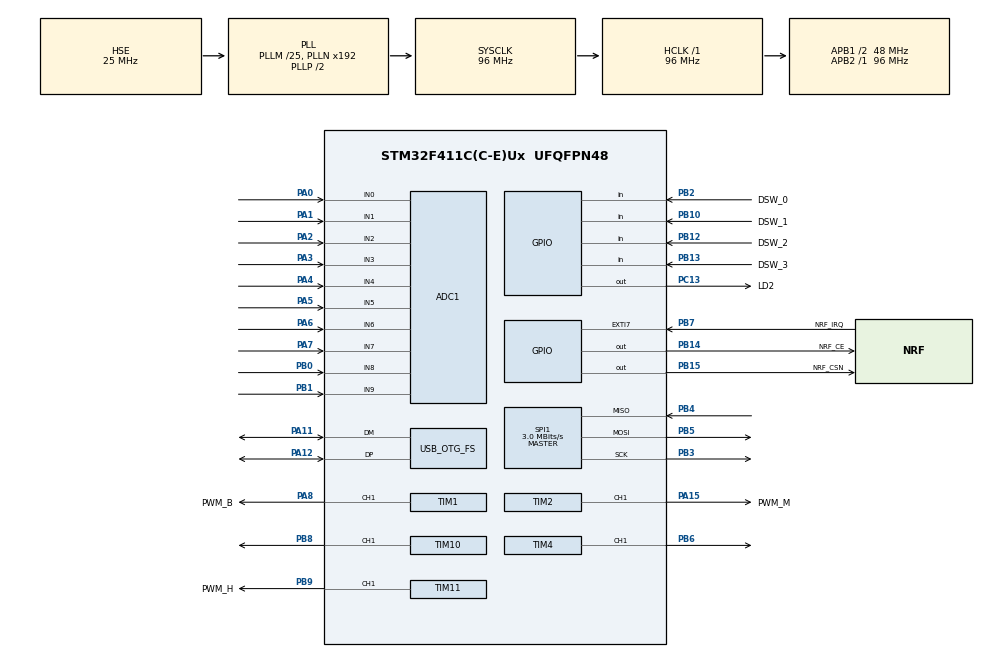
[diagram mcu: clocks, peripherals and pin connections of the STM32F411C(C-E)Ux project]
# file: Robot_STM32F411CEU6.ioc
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ADC1.Channel-0\#ChannelRegularConversion=ADC_CHANNEL_0
ADC1.NbrOfConversionFlag=1
ADC1.Rank-0\#ChannelRegularConversion=1
ADC1.SamplingTime-0\#ChannelRegularConversion=ADC_SAMPLETIME_3CYCLES
ADC1.master=1
Mcu.Family=STM32F4
Mcu.Name=STM32F411C(C-E)Ux
Mcu.Package=UFQFPN48
NVIC.OTG_FS_IRQn=true\:0\:0\:false\:false\:true\:false\:true\:true
NVIC.PriorityGroup=NVIC_PRIORITYGROUP_4
PA0-WKUP.Signal=ADCx_IN0
PA1.Signal=ADCx_IN1
PA11.Mode=Device_Only
PA11.Signal=USB_OTG_FS_DM
PA12.Mode=Device_Only
PA12.Signal=USB_OTG_FS_DP
PA13.Mode=Serial_Wire
PA13.Signal=SYS_JTMS-SWDIO
PA14.Mode=Serial_Wire
PA14.Signal=SYS_JTCK-SWCLK
PA15.GPIO_Label=PWM_M
PA15.GPIO_ModeDefaultPP=GPIO_MODE_AF_OD
PA15.Signal=S_TIM2_CH1_ETR
PA2.Signal=ADCx_IN2
PA3.Signal=ADCx_IN3
PA4.Signal=ADCx_IN4
PA5.Signal=ADCx_IN5
PA6.Signal=ADCx_IN6
PA7.Signal=ADCx_IN7
PA8.GPIO_Label=PWM_B
PA8.GPIO_ModeDefaultPP=GPIO_MODE_AF_OD
PA8.Signal=S_TIM1_CH1
PB0.Signal=ADCx_IN8
PB1.Signal=ADCx_IN9
PB10.GPIO_Label=DSW_1
PB10.GPIO_PuPd=GPIO_PULLUP
PB10.Signal=GPIO_Input
PB12.GPIO_Label=DSW_2
PB12.GPIO_PuPd=GPIO_PULLUP
PB12.Signal=GPIO_Input
PB13.GPIO_Label=DSW_3
PB13.GPIO_PuPd=GPIO_PULLUP
PB13.Signal=GPIO_Input
PB14.GPIO_Label=NRF_CE
PB14.Signal=GPIO_Output
PB15.GPIO_Label=NRF_CSN
PB15.Signal=GPIO_Output
PB2.GPIO_Label=DSW_0
PB2.GPIO_PuPd=GPIO_PULLUP
PB2.Signal=GPIO_Input
PB3.Mode=Full_Duplex_Master
PB3.Signal=SPI1_SCK
PB4.Mode=Full_Duplex_Master
PB4.Signal=SPI1_MISO
PB5.Mode=Full_Duplex_Master
PB5.Signal=SPI1_MOSI
PB6.Signal=S_TIM4_CH1
PB7.GPIO_Label=NRF_IRQ
PB7.Signal=GPXTI7
PB8.Signal=S_TIM10_CH1
PB9.GPIO_Label=PWM_H
PB9.GPIO_ModeDefaultPP=GPIO_MODE_AF_OD
PB9.Signal=S_TIM11_CH1
PC13-ANTI_TAMP.GPIO_Label=LD2
PC13-ANTI_TAMP.Signal=GPIO_Output
PC14-OSC32_IN.Mode=LSE-External-Oscillator
PC14-OSC32_IN.Signal=RCC_OSC32_IN
PC15-OSC32_OUT.Mode=LSE-External-Oscillator
PC15-OSC32_OUT.Signal=RCC_OSC32_OUT
PH0\ -\ OSC_IN.Mode=HSE-External-Oscillator
PH0\ -\ OSC_IN.Signal=RCC_OSC_IN
PH1\ -\ OSC_OUT.Mode=HSE-External-Oscillator
PH1\ -\ OSC_OUT.Signal=RCC_OSC_OUT
ProjectManager.HeapSize=0x200
ProjectManager.StackSize=0x400
ProjectManager.TargetToolchain=STM32CubeIDE
RCC.48MHZClocksFreq_Value=48000000
RCC.AHBFreq_Value=96000000
RCC.APB1CLKDivider=RCC_HCLK_DIV2
RCC.APB1Freq_Value=48000000
RCC.APB1TimCLKDivider=2
RCC.APB1TimFreq_Value=96000000
RCC.APB2Freq_Value=96000000
RCC.APB2TimFreq_Value=96000000
RCC.CortexFreq_Value=96000000
RCC.HCLKFreq_Value=96000000
RCC.HSE_VALUE=25000000
RCC.HSI_VALUE=16000000
RCC.PLLM=25
RCC.SYSCLKFreq_VALUE=96000000
RCC.SYSCLKSource=RCC_SYSCLKSOURCE_PLLCLK
RCC.VCOOutputFreq_Value=192000000
SH.ADCx_IN0.0=ADC1_IN0,IN0
SH.ADCx_IN1.0=ADC1_IN1,IN1
SH.ADCx_IN2.0=ADC1_IN2,IN2
SH.ADCx_IN3.0=ADC1_IN3,IN3
SH.ADCx_IN4.0=ADC1_IN4,IN4
SH.ADCx_IN5.0=ADC1_IN5,IN5
SH.ADCx_IN6.0=ADC1_IN6,IN6
SH.ADCx_IN7.0=ADC1_IN7,IN7
SH.ADCx_IN8.0=ADC1_IN8,IN8
SH.ADCx_IN9.0=ADC1_IN9,IN9
SH.S_TIM10_CH1.0=TIM10_CH1,PWM Generation1 CH1
SH.S_TIM11_CH1.0=TIM11_CH1,PWM Generation1 CH1
SH.S_TIM1_CH1.0=TIM1_CH1,PWM Generation1 CH1
SH.S_TIM2_CH1_ETR.0=TIM2_CH1,PWM Generation1 CH1
SH.S_TIM4_CH1.0=TIM4_CH1,PWM Generation1 CH1
SPI1.BaudRatePrescaler=SPI_BAUDRATEPRESCALER_32
SPI1.CalculateBaudRate=3.0 MBits/s
SPI1.Direction=SPI_DIRECTION_2LINES
SPI1.Mode=SPI_MODE_MASTER
SPI1.VirtualType=VM_MASTER
TIM1.Channel-PWM\ Generation1\ CH1=TIM_CHANNEL_1
TIM1.Period=19999
TIM1.Prescaler=95
TIM10.Channel=TIM_CHANNEL_1
TIM10.Period=65535
TIM10.Prescaler=0
TIM11.Channel=TIM_CHANNEL_1
TIM11.Period=20000
TIM11.Prescaler=95
TIM2.Channel-PWM\ Generation1\ CH1=TIM_CHANNEL_1
TIM2.Period=20000
TIM2.Prescaler=95
TIM4.Channel-PWM\ Generation1\ CH1=TIM_CHANNEL_1
USB_DEVICE.CLASS_NAME_FS=CDC
USB_DEVICE.VirtualMode=Cdc
USB_DEVICE.VirtualModeFS=Cdc_FS
USB_OTG_FS.VirtualMode=Device_Only
VP_TIM10_VS_ClockSourceINT.Mode=Enable_Timer
VP_TIM11_VS_ClockSourceINT.Mode=Enable_Timer
VP_USB_DEVICE_VS_USB_DEVICE_CDC_FS.Mode=CDC_FS
board=custom

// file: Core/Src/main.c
/* USER CODE BEGIN Header */
/**
  ******************************************************************************
  * @file           : main.c
  * @brief          : Main program body
  ******************************************************************************
  * @attention
  *
  * Copyright (c) 2025 STMicroelectronics.
  * All rights reserved.
  *
  * This software is licensed under terms that can be found in the LICENSE file
  * in the root directory of this software component.
  * If no LICENSE file comes with this software, it is provided AS-IS.
  *
  ******************************************************************************
  */
/* USER CODE END Header */
#include "main.h"
#include "usb_device.h"

/* USER CODE BEGIN Includes */
#include "movement.h"
/* USER CODE END Includes */

ADC_HandleTypeDef hadc1;

SPI_HandleTypeDef hspi1;

TIM_HandleTypeDef htim1;
TIM_HandleTypeDef htim2;
TIM_HandleTypeDef htim4;
TIM_HandleTypeDef htim10;
TIM_HandleTypeDef htim11;

void SystemClock_Config(void);
static void MX_GPIO_Init(void);
static void MX_ADC1_Init(void);
static void MX_SPI1_Init(void);
static void MX_TIM1_Init(void);
static void MX_TIM2_Init(void);
static void MX_TIM4_Init(void);
static void MX_TIM10_Init(void);
static void MX_TIM11_Init(void);

int main(void)
{

  /* MCU Configuration--------------------------------------------------------*/

  /* Reset of all peripherals, Initializes the Flash interface and the Systick. */
  HAL_Init();

  /* Configure the system clock */
  SystemClock_Config();

  /* Initialize all configured peripherals */
  MX_GPIO_Init();
  MX_ADC1_Init();
  MX_SPI1_Init();
  MX_USB_DEVICE_Init();
  MX_TIM1_Init();
  MX_TIM2_Init();
  MX_TIM4_Init();
  MX_TIM10_Init();
  MX_TIM11_Init();
  /* USER CODE BEGIN 2 */
  movement();
  /* USER CODE END 2 */

  /* Infinite loop */
  while (1)
  {

  }
}

void SystemClock_Config(void)
{
  RCC_OscInitTypeDef RCC_OscInitStruct = {0};
  RCC_ClkInitTypeDef RCC_ClkInitStruct = {0};

  /** Configure the main internal regulator output voltage
  */
  __HAL_RCC_PWR_CLK_ENABLE();
  __HAL_PWR_VOLTAGESCALING_CONFIG(PWR_REGULATOR_VOLTAGE_SCALE1);

  /** Initializes the RCC Oscillators according to the specified parameters
  * in the RCC_OscInitTypeDef structure.
  */
  RCC_OscInitStruct.OscillatorType = RCC_OSCILLATORTYPE_HSE;
  RCC_OscInitStruct.HSEState = RCC_HSE_ON;
  RCC_OscInitStruct.PLL.PLLState = RCC_PLL_ON;
  RCC_OscInitStruct.PLL.PLLSource = RCC_PLLSOURCE_HSE;
  RCC_OscInitStruct.PLL.PLLM = 25;
  RCC_OscInitStruct.PLL.PLLN = 192;
  RCC_OscInitStruct.PLL.PLLP = RCC_PLLP_DIV2;
  RCC_OscInitStruct.PLL.PLLQ = 4;
  if (HAL_RCC_OscConfig(&RCC_OscInitStruct) != HAL_OK)
  {
    Error_Handler();
  }

  /** Initializes the CPU, AHB and APB buses clocks
  */
  RCC_ClkInitStruct.ClockType = RCC_CLOCKTYPE_HCLK|RCC_CLOCKTYPE_SYSCLK
                              |RCC_CLOCKTYPE_PCLK1|RCC_CLOCKTYPE_PCLK2;
  RCC_ClkInitStruct.SYSCLKSource = RCC_SYSCLKSOURCE_PLLCLK;
  RCC_ClkInitStruct.AHBCLKDivider = RCC_SYSCLK_DIV1;
  RCC_ClkInitStruct.APB1CLKDivider = RCC_HCLK_DIV2;
  RCC_ClkInitStruct.APB2CLKDivider = RCC_HCLK_DIV1;

  if (HAL_RCC_ClockConfig(&RCC_ClkInitStruct, FLASH_LATENCY_3) != HAL_OK)
  {
    Error_Handler();
  }
}

static void MX_ADC1_Init(void)
{

  ADC_ChannelConfTypeDef sConfig = {0};

  /** Configure the global features of the ADC (Clock, Resolution, Data Alignment and number of conversion)
  */
  hadc1.Instance = ADC1;
  hadc1.Init.ClockPrescaler = ADC_CLOCK_SYNC_PCLK_DIV4;
  hadc1.Init.Resolution = ADC_RESOLUTION_12B;
  hadc1.Init.ScanConvMode = DISABLE;
  hadc1.Init.ContinuousConvMode = DISABLE;
  hadc1.Init.DiscontinuousConvMode = DISABLE;
  hadc1.Init.ExternalTrigConvEdge = ADC_EXTERNALTRIGCONVEDGE_NONE;
  hadc1.Init.ExternalTrigConv = ADC_SOFTWARE_START;
  hadc1.Init.DataAlign = ADC_DATAALIGN_RIGHT;
  hadc1.Init.NbrOfConversion = 1;
  hadc1.Init.DMAContinuousRequests = DISABLE;
  hadc1.Init.EOCSelection = ADC_EOC_SINGLE_CONV;
  if (HAL_ADC_Init(&hadc1) != HAL_OK)
  {
    Error_Handler();
  }

  /** Configure for the selected ADC regular channel its corresponding rank in the sequencer and its sample time.
  */
  sConfig.Channel = ADC_CHANNEL_0;
  sConfig.Rank = 1;
  sConfig.SamplingTime = ADC_SAMPLETIME_3CYCLES;
  if (HAL_ADC_ConfigChannel(&hadc1, &sConfig) != HAL_OK)
  {
    Error_Handler();
  }

}

static void MX_SPI1_Init(void)
{

  /* SPI1 parameter configuration*/
  hspi1.Instance = SPI1;
  hspi1.Init.Mode = SPI_MODE_MASTER;
  hspi1.Init.Direction = SPI_DIRECTION_2LINES;
  hspi1.Init.DataSize = SPI_DATASIZE_8BIT;
  hspi1.Init.CLKPolarity = SPI_POLARITY_LOW;
  hspi1.Init.CLKPhase = SPI_PHASE_1EDGE;
  hspi1.Init.NSS = SPI_NSS_SOFT;
  hspi1.Init.BaudRatePrescaler = SPI_BAUDRATEPRESCALER_32;
  hspi1.Init.FirstBit = SPI_FIRSTBIT_MSB;
  hspi1.Init.TIMode = SPI_TIMODE_DISABLE;
  hspi1.Init.CRCCalculation = SPI_CRCCALCULATION_DISABLE;
  hspi1.Init.CRCPolynomial = 10;
  if (HAL_SPI_Init(&hspi1) != HAL_OK)
  {
    Error_Handler();
  }

}

static void MX_TIM1_Init(void)
{

  TIM_MasterConfigTypeDef sMasterConfig = {0};
  TIM_OC_InitTypeDef sConfigOC = {0};
  TIM_BreakDeadTimeConfigTypeDef sBreakDeadTimeConfig = {0};

  htim1.Instance = TIM1;
  htim1.Init.Prescaler = 95;
  htim1.Init.CounterMode = TIM_COUNTERMODE_UP;
  htim1.Init.Period = 19999;
  htim1.Init.ClockDivision = TIM_CLOCKDIVISION_DIV1;
  htim1.Init.RepetitionCounter = 0;
  htim1.Init.AutoReloadPreload = TIM_AUTORELOAD_PRELOAD_DISABLE;
  if (HAL_TIM_PWM_Init(&htim1) != HAL_OK)
  {
    Error_Handler();
  }
  sMasterConfig.MasterOutputTrigger = TIM_TRGO_RESET;
  sMasterConfig.MasterSlaveMode = TIM_MASTERSLAVEMODE_DISABLE;
  if (HAL_TIMEx_MasterConfigSynchronization(&htim1, &sMasterConfig) != HAL_OK)
  {
    Error_Handler();
  }
  sConfigOC.OCMode = TIM_OCMODE_PWM1;
  sConfigOC.Pulse = 0;
  sConfigOC.OCPolarity = TIM_OCPOLARITY_HIGH;
  sConfigOC.OCNPolarity = TIM_OCNPOLARITY_HIGH;
  sConfigOC.OCFastMode = TIM_OCFAST_DISABLE;
  sConfigOC.OCIdleState = TIM_OCIDLESTATE_RESET;
  sConfigOC.OCNIdleState = TIM_OCNIDLESTATE_RESET;
  if (HAL_TIM_PWM_ConfigChannel(&htim1, &sConfigOC, TIM_CHANNEL_1) != HAL_OK)
  {
    Error_Handler();
  }
  sBreakDeadTimeConfig.OffStateRunMode = TIM_OSSR_DISABLE;
  sBreakDeadTimeConfig.OffStateIDLEMode = TIM_OSSI_DISABLE;
  sBreakDeadTimeConfig.LockLevel = TIM_LOCKLEVEL_OFF;
  sBreakDeadTimeConfig.DeadTime = 0;
  sBreakDeadTimeConfig.BreakState = TIM_BREAK_DISABLE;
  sBreakDeadTimeConfig.BreakPolarity = TIM_BREAKPOLARITY_HIGH;
  sBreakDeadTimeConfig.AutomaticOutput = TIM_AUTOMATICOUTPUT_DISABLE;
  if (HAL_TIMEx_ConfigBreakDeadTime(&htim1, &sBreakDeadTimeConfig) != HAL_OK)
  {
    Error_Handler();
  }
  HAL_TIM_MspPostInit(&htim1);

}

static void MX_TIM2_Init(void)
{

  TIM_MasterConfigTypeDef sMasterConfig = {0};
  TIM_OC_InitTypeDef sConfigOC = {0};

  htim2.Instance = TIM2;
  htim2.Init.Prescaler = 95;
  htim2.Init.CounterMode = TIM_COUNTERMODE_UP;
  htim2.Init.Period = 20000;
  htim2.Init.ClockDivision = TIM_CLOCKDIVISION_DIV1;
  htim2.Init.AutoReloadPreload = TIM_AUTORELOAD_PRELOAD_DISABLE;
  if (HAL_TIM_PWM_Init(&htim2) != HAL_OK)
  {
    Error_Handler();
  }
  sMasterConfig.MasterOutputTrigger = TIM_TRGO_RESET;
  sMasterConfig.MasterSlaveMode = TIM_MASTERSLAVEMODE_DISABLE;
  if (HAL_TIMEx_MasterConfigSynchronization(&htim2, &sMasterConfig) != HAL_OK)
  {
    Error_Handler();
  }
  sConfigOC.OCMode = TIM_OCMODE_PWM1;
  sConfigOC.Pulse = 0;
  sConfigOC.OCPolarity = TIM_OCPOLARITY_HIGH;
  sConfigOC.OCFastMode = TIM_OCFAST_DISABLE;
  if (HAL_TIM_PWM_ConfigChannel(&htim2, &sConfigOC, TIM_CHANNEL_1) != HAL_OK)
  {
    Error_Handler();
  }
  HAL_TIM_MspPostInit(&htim2);

}

static void MX_TIM4_Init(void)
{

  TIM_MasterConfigTypeDef sMasterConfig = {0};
  TIM_OC_InitTypeDef sConfigOC = {0};

  htim4.Instance = TIM4;
  htim4.Init.Prescaler = 0;
  htim4.Init.CounterMode = TIM_COUNTERMODE_UP;
  htim4.Init.Period = 65535;
  htim4.Init.ClockDivision = TIM_CLOCKDIVISION_DIV1;
  htim4.Init.AutoReloadPreload = TIM_AUTORELOAD_PRELOAD_DISABLE;
  if (HAL_TIM_PWM_Init(&htim4) != HAL_OK)
  {
    Error_Handler();
  }
  sMasterConfig.MasterOutputTrigger = TIM_TRGO_RESET;
  sMasterConfig.MasterSlaveMode = TIM_MASTERSLAVEMODE_DISABLE;
  if (HAL_TIMEx_MasterConfigSynchronization(&htim4, &sMasterConfig) != HAL_OK)
  {
    Error_Handler();
  }
  sConfigOC.OCMode = TIM_OCMODE_PWM1;
  sConfigOC.Pulse = 0;
  sConfigOC.OCPolarity = TIM_OCPOLARITY_HIGH;
  sConfigOC.OCFastMode = TIM_OCFAST_DISABLE;
  if (HAL_TIM_PWM_ConfigChannel(&htim4, &sConfigOC, TIM_CHANNEL_1) != HAL_OK)
  {
    Error_Handler();
  }
  HAL_TIM_MspPostInit(&htim4);

}

static void MX_TIM10_Init(void)
{

  TIM_OC_InitTypeDef sConfigOC = {0};

  htim10.Instance = TIM10;
  htim10.Init.Prescaler = 0;
  htim10.Init.CounterMode = TIM_COUNTERMODE_UP;
  htim10.Init.Period = 65535;
  htim10.Init.ClockDivision = TIM_CLOCKDIVISION_DIV1;
  htim10.Init.AutoReloadPreload = TIM_AUTORELOAD_PRELOAD_DISABLE;
  if (HAL_TIM_Base_Init(&htim10) != HAL_OK)
  {
    Error_Handler();
  }
  if (HAL_TIM_PWM_Init(&htim10) != HAL_OK)
  {
    Error_Handler();
  }
  sConfigOC.OCMode = TIM_OCMODE_PWM1;
  sConfigOC.Pulse = 0;
  sConfigOC.OCPolarity = TIM_OCPOLARITY_HIGH;
  sConfigOC.OCFastMode = TIM_OCFAST_DISABLE;
  if (HAL_TIM_PWM_ConfigChannel(&htim10, &sConfigOC, TIM_CHANNEL_1) != HAL_OK)
  {
    Error_Handler();
  }
  HAL_TIM_MspPostInit(&htim10);

}

static void MX_TIM11_Init(void)
{

  TIM_OC_InitTypeDef sConfigOC = {0};

  htim11.Instance = TIM11;
  htim11.Init.Prescaler = 95;
  htim11.Init.CounterMode = TIM_COUNTERMODE_UP;
  htim11.Init.Period = 20000;
  htim11.Init.ClockDivision = TIM_CLOCKDIVISION_DIV1;
  htim11.Init.AutoReloadPreload = TIM_AUTORELOAD_PRELOAD_DISABLE;
  if (HAL_TIM_Base_Init(&htim11) != HAL_OK)
  {
    Error_Handler();
  }
  if (HAL_TIM_PWM_Init(&htim11) != HAL_OK)
  {
    Error_Handler();
  }
  sConfigOC.OCMode = TIM_OCMODE_PWM1;
  sConfigOC.Pulse = 0;
  sConfigOC.OCPolarity = TIM_OCPOLARITY_HIGH;
  sConfigOC.OCFastMode = TIM_OCFAST_DISABLE;
  if (HAL_TIM_PWM_ConfigChannel(&htim11, &sConfigOC, TIM_CHANNEL_1) != HAL_OK)
  {
    Error_Handler();
  }
  HAL_TIM_MspPostInit(&htim11);

}

static void MX_GPIO_Init(void)
{
  GPIO_InitTypeDef GPIO_InitStruct = {0};

  /* GPIO Ports Clock Enable */
  __HAL_RCC_GPIOC_CLK_ENABLE();
  __HAL_RCC_GPIOH_CLK_ENABLE();
  __HAL_RCC_GPIOA_CLK_ENABLE();
  __HAL_RCC_GPIOB_CLK_ENABLE();

  /*Configure GPIO pin Output Level */
  HAL_GPIO_WritePin(LD2_GPIO_Port, LD2_Pin, GPIO_PIN_RESET);

  /*Configure GPIO pin Output Level */
  HAL_GPIO_WritePin(GPIOB, NRF_CE_Pin|NRF_CSN_Pin, GPIO_PIN_RESET);

  /*Configure GPIO pin : LD2_Pin */
  GPIO_InitStruct.Pin = LD2_Pin;
  GPIO_InitStruct.Mode = GPIO_MODE_OUTPUT_PP;
  GPIO_InitStruct.Pull = GPIO_NOPULL;
  GPIO_InitStruct.Speed = GPIO_SPEED_FREQ_LOW;
  HAL_GPIO_Init(LD2_GPIO_Port, &GPIO_InitStruct);

  /*Configure GPIO pins : DSW_0_Pin DSW_1_Pin DSW_2_Pin DSW_3_Pin */
  GPIO_InitStruct.Pin = DSW_0_Pin|DSW_1_Pin|DSW_2_Pin|DSW_3_Pin;
  GPIO_InitStruct.Mode = GPIO_MODE_INPUT;
  GPIO_InitStruct.Pull = GPIO_PULLUP;
  HAL_GPIO_Init(GPIOB, &GPIO_InitStruct);

  /*Configure GPIO pins : NRF_CE_Pin NRF_CSN_Pin */
  GPIO_InitStruct.Pin = NRF_CE_Pin|NRF_CSN_Pin;
  GPIO_InitStruct.Mode = GPIO_MODE_OUTPUT_PP;
  GPIO_InitStruct.Pull = GPIO_NOPULL;
  GPIO_InitStruct.Speed = GPIO_SPEED_FREQ_LOW;
  HAL_GPIO_Init(GPIOB, &GPIO_InitStruct);

  /*Configure GPIO pin : NRF_IRQ_Pin */
  GPIO_InitStruct.Pin = NRF_IRQ_Pin;
  GPIO_InitStruct.Mode = GPIO_MODE_IT_RISING;
  GPIO_InitStruct.Pull = GPIO_NOPULL;
  HAL_GPIO_Init(NRF_IRQ_GPIO_Port, &GPIO_InitStruct);

}

void Error_Handler(void)
{
  __disable_irq();
  while (1)
  {
  }
}
